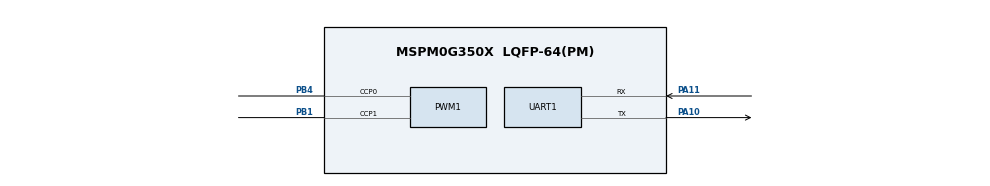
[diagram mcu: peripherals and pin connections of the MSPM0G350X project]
/**
 * @cliArgs --device "MSPM0G350X" --package "LQFP-64(PM)" --part "Default" --product "mspm0_sdk@2.01.00.03"
 * @versions {"tool":"1.20.0+3587"}
 */

/**
 * Import the modules used in this configuration.
 */
const GPIO    = scripting.addModule("/ti/driverlib/GPIO", {}, false);
const GPIO1   = GPIO.addInstance();
const GPIO2   = GPIO.addInstance();
const GPIO3   = GPIO.addInstance();
const GPIO4   = GPIO.addInstance();
const GPIO5   = GPIO.addInstance();
const GPIO6   = GPIO.addInstance();
const GPIO7   = GPIO.addInstance();
const GPIO8   = GPIO.addInstance();
const GPIO9   = GPIO.addInstance();
const GPIO10  = GPIO.addInstance();
const GPIO11  = GPIO.addInstance();
const GPIO12  = GPIO.addInstance();
const PWM     = scripting.addModule("/ti/driverlib/PWM", {}, false);
const PWM1    = PWM.addInstance();
const SYSCTL  = scripting.addModule("/ti/driverlib/SYSCTL");
const SYSTICK = scripting.addModule("/ti/driverlib/SYSTICK");
const TIMER   = scripting.addModule("/ti/driverlib/TIMER", {}, false);
const TIMER1  = TIMER.addInstance();
const UART    = scripting.addModule("/ti/driverlib/UART", {}, false);
const UART1   = UART.addInstance();

/**
 * Write custom configuration values to the imported modules.
 */
const gate7  = system.clockTree["MFCLKGATE"];
gate7.enable = true;

GPIO1.$name                          = "LED1";
GPIO1.associatedPins[0].$name        = "PIN_0";
GPIO1.associatedPins[0].assignedPort = "PORTA";
GPIO1.associatedPins[0].assignedPin  = "28";

const Board = scripting.addModule("/ti/driverlib/Board", {}, false);

GPIO2.$name                          = "KEY";
GPIO2.associatedPins[0].$name        = "PIN_21";
GPIO2.associatedPins[0].direction    = "INPUT";
GPIO2.associatedPins[0].assignedPort = "PORTB";
GPIO2.associatedPins[0].assignedPin  = "21";

GPIO3.$name                          = "ENCODERA";
GPIO3.associatedPins.create(2);
GPIO3.associatedPins[0].$name        = "E1A";
GPIO3.associatedPins[0].direction    = "INPUT";
GPIO3.associatedPins[0].assignedPort = "PORTA";
GPIO3.associatedPins[0].interruptEn  = true;
GPIO3.associatedPins[0].polarity     = "RISE";
GPIO3.associatedPins[0].assignedPin  = "15";
GPIO3.associatedPins[1].$name        = "E1B";
GPIO3.associatedPins[1].direction    = "INPUT";
GPIO3.associatedPins[1].assignedPort = "PORTA";
GPIO3.associatedPins[1].assignedPin  = "16";
GPIO3.associatedPins[1].interruptEn  = true;
GPIO3.associatedPins[1].polarity     = "RISE";

GPIO4.$name                          = "ENCODERB";
GPIO4.associatedPins.create(2);
GPIO4.associatedPins[0].$name        = "E2A";
GPIO4.associatedPins[0].direction    = "INPUT";
GPIO4.associatedPins[0].interruptEn  = true;
GPIO4.associatedPins[0].polarity     = "RISE";
GPIO4.associatedPins[0].assignedPin  = "17";
GPIO4.associatedPins[0].assignedPort = "PORTA";
GPIO4.associatedPins[1].$name        = "E2B";
GPIO4.associatedPins[1].direction    = "INPUT";
GPIO4.associatedPins[1].interruptEn  = true;
GPIO4.associatedPins[1].polarity     = "RISE";
GPIO4.associatedPins[1].assignedPort = "PORTA";
GPIO4.associatedPins[1].assignedPin  = "22";

GPIO5.$name                          = "AIN1";
GPIO5.associatedPins[0].$name        = "PIN_12";
GPIO5.associatedPins[0].assignedPort = "PORTA";
GPIO5.associatedPins[0].assignedPin  = "12";

GPIO6.$name                          = "AIN2";
GPIO6.associatedPins[0].$name        = "PIN_13";
GPIO6.associatedPins[0].assignedPort = "PORTA";
GPIO6.associatedPins[0].assignedPin  = "13";

GPIO7.$name                          = "BIN1";
GPIO7.associatedPins[0].$name        = "Pin_Bin1";
GPIO7.associatedPins[0].assignedPort = "PORTB";
GPIO7.associatedPins[0].assignedPin  = "16";

GPIO8.$name                          = "BIN2";
GPIO8.associatedPins[0].$name        = "Pin_Bin2";
GPIO8.associatedPins[0].assignedPort = "PORTB";
GPIO8.associatedPins[0].assignedPin  = "0";

GPIO9.$name                          = "I2C";
GPIO9.associatedPins.create(2);
GPIO9.associatedPins[0].$name        = "SCL";
GPIO9.associatedPins[0].initialValue = "SET";
GPIO9.associatedPins[0].ioStructure  = "OD";
GPIO9.associatedPins[0].assignedPort = "PORTA";
GPIO9.associatedPins[0].assignedPin  = "0";
GPIO9.associatedPins[1].$name        = "SDA";
GPIO9.associatedPins[1].initialValue = "SET";
GPIO9.associatedPins[1].ioStructure  = "OD";
GPIO9.associatedPins[1].assignedPort = "PORTA";
GPIO9.associatedPins[1].assignedPin  = "1";

GPIO10.$name                          = "BEER";
GPIO10.associatedPins[0].$name        = "PIN_1";
GPIO10.associatedPins[0].initialValue = "SET";
GPIO10.associatedPins[0].assignedPort = "PORTA";
GPIO10.associatedPins[0].assignedPin  = "27";

GPIO11.$name                          = "LINE4";
GPIO11.associatedPins.create(8);
GPIO11.associatedPins[0].$name        = "PIN_41";
GPIO11.associatedPins[0].assignedPort = "PORTB";
GPIO11.associatedPins[0].assignedPin  = "8";
GPIO11.associatedPins[0].direction    = "INPUT";
GPIO11.associatedPins[1].$name        = "PIN_42";
GPIO11.associatedPins[1].direction    = "INPUT";
GPIO11.associatedPins[1].assignedPort = "PORTB";
GPIO11.associatedPins[1].assignedPin  = "7";
GPIO11.associatedPins[2].$name        = "PIN_43";
GPIO11.associatedPins[2].direction    = "INPUT";
GPIO11.associatedPins[2].assignedPort = "PORTB";
GPIO11.associatedPins[2].assignedPin  = "6";
GPIO11.associatedPins[3].$name        = "PIN_44";
GPIO11.associatedPins[3].direction    = "INPUT";
GPIO11.associatedPins[3].assignedPort = "PORTB";
GPIO11.associatedPins[3].assignedPin  = "15";
GPIO11.associatedPins[4].$name        = "PIN_45";
GPIO11.associatedPins[4].direction    = "INPUT";
GPIO11.associatedPins[4].assignedPort = "PORTB";
GPIO11.associatedPins[4].assignedPin  = "12";
GPIO11.associatedPins[5].$name        = "PIN_46";
GPIO11.associatedPins[5].direction    = "INPUT";
GPIO11.associatedPins[5].assignedPort = "PORTB";
GPIO11.associatedPins[5].assignedPin  = "17";
GPIO11.associatedPins[6].$name        = "PIN_47";
GPIO11.associatedPins[6].direction    = "INPUT";
GPIO11.associatedPins[6].assignedPort = "PORTB";
GPIO11.associatedPins[6].assignedPin  = "20";
GPIO11.associatedPins[7].$name        = "PIN_48";
GPIO11.associatedPins[7].direction    = "INPUT";
GPIO11.associatedPins[7].assignedPort = "PORTB";
GPIO11.associatedPins[7].assignedPin  = "13";

GPIO12.$name                              = "KEY1";
GPIO12.associatedPins.create(2);
GPIO12.associatedPins[0].$name            = "PIN_18";
GPIO12.associatedPins[0].direction        = "INPUT";
GPIO12.associatedPins[0].assignedPort     = "PORTA";
GPIO12.associatedPins[0].assignedPin      = "18";
GPIO12.associatedPins[1].$name            = "PIN_out";
GPIO12.associatedPins[1].assignedPort     = "PORTA";
GPIO12.associatedPins[1].internalResistor = "PULL_UP";
GPIO12.associatedPins[1].assignedPin      = "24";

PWM1.$name                      = "PWM_0";
PWM1.timerCount                 = 3200;
PWM1.timerStartTimer            = true;
PWM1.pwmMode                    = "EDGE_ALIGN_UP";
PWM1.peripheral.ccp0Pin.$assign = "PB4";
PWM1.peripheral.ccp1Pin.$assign = "PB1";
PWM1.PWM_CHANNEL_0.$name        = "ti_driverlib_pwm_PWMTimerCC0";
PWM1.PWM_CHANNEL_1.$name        = "ti_driverlib_pwm_PWMTimerCC1";
PWM1.ccp0PinConfig.$name        = "ti_driverlib_gpio_GPIOPinGeneric2";
PWM1.ccp1PinConfig.$name        = "ti_driverlib_gpio_GPIOPinGeneric3";

SYSCTL.forceDefaultClkConfig = true;
SYSCTL.clockTreeEn           = true;

SYSTICK.periodEnable  = true;
SYSTICK.period        = 32;
SYSTICK.systickEnable = true;

TIMER1.$name            = "TIMER_0";
TIMER1.timerClkDiv      = 8;
TIMER1.timerStartTimer  = true;
TIMER1.interrupts       = ["ZERO"];
TIMER1.timerMode        = "PERIODIC";
TIMER1.timerClkPrescale = 200;
TIMER1.timerPeriod      = "100 ms";

UART1.$name                    = "UART_0";
UART1.uartClkSrc               = "MFCLK";
UART1.enabledInterrupts        = ["RX"];
UART1.peripheral.rxPin.$assign = "PA11";
UART1.peripheral.txPin.$assign = "PA10";
UART1.txPinConfig.$name        = "ti_driverlib_gpio_GPIOPinGeneric0";
UART1.rxPinConfig.$name        = "ti_driverlib_gpio_GPIOPinGeneric1";

/**
 * Pinmux solution for unlocked pins/peripherals. This ensures that minor changes to the automatic solver in a future
 * version of the tool will not impact the pinmux you originally saw.  These lines can be completely deleted in order to
 * re-solve from scratch.
 */
GPIO1.associatedPins[0].pin.$suggestSolution  = "PA28";
Board.peripheral.$suggestSolution             = "DEBUGSS";
Board.peripheral.swclkPin.$suggestSolution    = "PA20";
Board.peripheral.swdioPin.$suggestSolution    = "PA19";
GPIO2.associatedPins[0].pin.$suggestSolution  = "PB21";
GPIO3.associatedPins[0].pin.$suggestSolution  = "PA15";
GPIO3.associatedPins[1].pin.$suggestSolution  = "PA16";
GPIO4.associatedPins[0].pin.$suggestSolution  = "PA17";
GPIO4.associatedPins[1].pin.$suggestSolution  = "PA22";
GPIO5.associatedPins[0].pin.$suggestSolution  = "PA12";
GPIO6.associatedPins[0].pin.$suggestSolution  = "PA13";
GPIO7.associatedPins[0].pin.$suggestSolution  = "PB16";
GPIO8.associatedPins[0].pin.$suggestSolution  = "PB0";
GPIO9.associatedPins[0].pin.$suggestSolution  = "PA0";
GPIO9.associatedPins[1].pin.$suggestSolution  = "PA1";
GPIO10.associatedPins[0].pin.$suggestSolution = "PA27";
GPIO11.associatedPins[0].pin.$suggestSolution = "PB8";
GPIO11.associatedPins[1].pin.$suggestSolution = "PB7";
GPIO11.associatedPins[2].pin.$suggestSolution = "PB6";
GPIO11.associatedPins[3].pin.$suggestSolution = "PB15";
GPIO11.associatedPins[4].pin.$suggestSolution = "PB12";
GPIO11.associatedPins[5].pin.$suggestSolution = "PB17";
GPIO11.associatedPins[6].pin.$suggestSolution = "PB20";
GPIO11.associatedPins[7].pin.$suggestSolution = "PB13";
GPIO12.associatedPins[0].pin.$suggestSolution = "PA18";
GPIO12.associatedPins[1].pin.$suggestSolution = "PA24";
PWM1.peripheral.$suggestSolution              = "TIMA1";
TIMER1.peripheral.$suggestSolution            = "TIMA0";
UART1.peripheral.$suggestSolution             = "UART0";
